# AT32F405xx_v2 register map
Vendor: Keil; Series: AT32F405; File version: 1.0
CPU: CM4 r0p1, little endian, no MPU, FPU, 4 interrupt priority bits
Registers are 32-bit, read-write, reset 0x0 unless marked. A register's access mark holds for its fields unless they carry their own. Offsets are from the block's base; [hi:lo] are bit positions; {n}, {i} and the like mark numbered series; 'fields as' and 'values as' point back to an identical list.

## USB_OTGHS_HOST — USB on the go high speed
Base 0x40040400
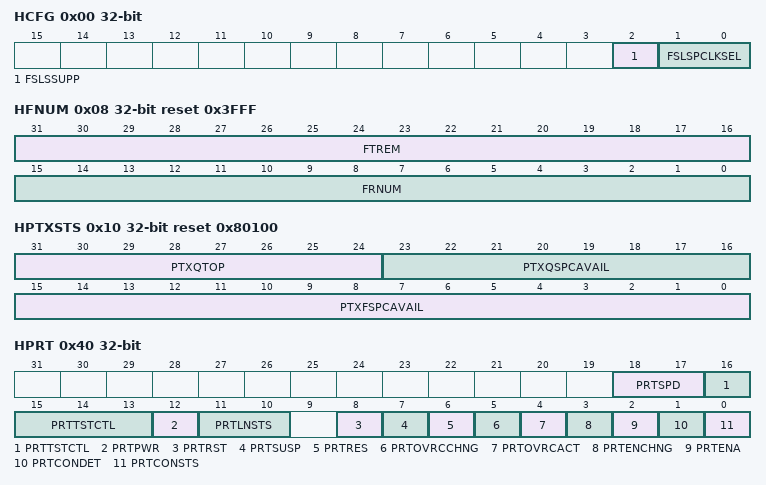
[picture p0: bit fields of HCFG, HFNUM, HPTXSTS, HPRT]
0x00 HCFG — OTGHS host configuration register (OTGHS_HCFG)
  [2] FSLSSUPP ro — FS- and LS-only support
  [1:0] FSLSPCLKSEL — FS/LS PHY clock select
0x04 HFIR reset 0xEA60 — OTGHS Host frame interval register
  [15:0] FRINT — Frame interval
0x08 HFNUM ro reset 0x3FFF — OTGHS host frame number/frame time remaining register (OTGHS_HFNUM)
  [31:16] FTREM — Frame time remaining
  [15:0] FRNUM — Frame number
0x10 HPTXSTS reset 0x80100 — OTGHS_Host periodic transmit FIFO/queue status register (OTGHS_HPTXSTS)
  [31:24] PTXQTOP ro — Top of the periodic transmit request queue
  [23:16] PTXQSPCAVAIL ro — Periodic transmit request queue space available
  [15:0] PTXFSPCAVAIL ro — Periodic transmit data FIFO space available
0x14 HAINT ro — OTGHS Host all channels interrupt register
  [15:0] HAINT — Channel interrupts
0x18 HAINTMSK — OTGHS host all channels interrupt mask register
  [15:0] HAINTMSK — Channel interrupt mask
0x40 HPRT — OTGHS host port control and status register (OTGHS_HPRT)
  [18:17] PRTSPD ro — Port speed
  [16:13] PRTTSTCTL — Port test control
  [12] PRTPWR — Port power
  [11:10] PRTLNSTS ro — Port line status
  [8] PRTRST — Port reset
  [7] PRTSUSP — Port suspend
  [6] PRTRES — Port resume
  [5] PRTOVRCCHNG — Port overcurrent change
  [4] PRTOVRCACT ro — Port overcurrent active
  [3] PRTENCHNG — Port enable/disable change
  [2] PRTENA — Port enable
  [1] PRTCONDET — Port connect detected
  [0] PRTCONSTS ro — Port connect status
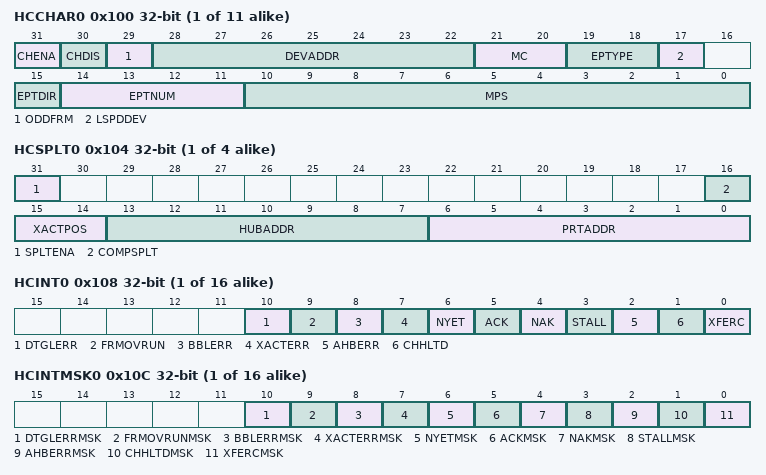
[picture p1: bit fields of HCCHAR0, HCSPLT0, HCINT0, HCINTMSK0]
{0x100+0x20*i} HCCHAR{i} (i=0..10) — OTGHS host channel-{i} characteristics register (OTGHS_HCCHAR{i})
  [31] CHENA — Channel enable
  [30] CHDIS — Channel disable
  [29] ODDFRM — Odd frame
  [28:22] DEVADDR — Device address
  [21:20] MC — Multicount
  [19:18] EPTYPE — Endpoint type
  [17] LSPDDEV — Low-speed device
  [15] EPTDIR — Endpoint direction
  [14:11] EPTNUM — Endpoint number
  [10:0] MPS — Maximum packet size
{0x104+0x20*i} HCSPLT{i} (i=0..3) — Host Channel {i} Split Control Register
  [31] SPLTENA — Split Enable
  [16] COMPSPLT — Do Complete Split
  [15:14] XACTPOS — Transaction Position
  [13:7] HUBADDR — Hub Address
  [6:0] PRTADDR — Port Address
{0x108+0x20*i} HCINT{i} (i=0..15) — OTGHS host channel-{i} interrupt register (OTGHS_HCINT{i})
  [10] DTGLERR — Data toggle error
  [9] FRMOVRUN — Frame overrun
  [8] BBLERR — Babble error
  [7] XACTERR — Transaction error
  [6] NYET — NYET Response Received interrupt
  [5] ACK — ACK response received/transmitted interrupt
  [4] NAK — NAK response received interrupt
  [3] STALL — STALL response received interrupt
  [2] AHBERR — AHB Error
  [1] CHHLTD — Channel halted
  [0] XFERC — Transfer completed
{0x10C+0x20*i} HCINTMSK{i} (i=0..15) — OTGHS host channel-{i} mask register (OTGHS_HCINTMSK{i})
  [10] DTGLERRMSK — Data toggle error mask
  [9] FRMOVRUNMSK — Frame overrun mask
  [8] BBLERRMSK — Babble error mask
  [7] XACTERRMSK — Transaction error mask
  [6] NYETMSK — NYET Response Received interrupt mask
  [5] ACKMSK — ACK response received/transmitted interrupt mask
  [4] NAKMSK — NAK response received interrupt mask
  [3] STALLMSK — STALL response received interrupt mask
  [2] AHBERRMSK — AHB Error Mask
  [1] CHHLTDMSK — Channel halted mask
  [0] XFERCMSK — Transfer completed mask
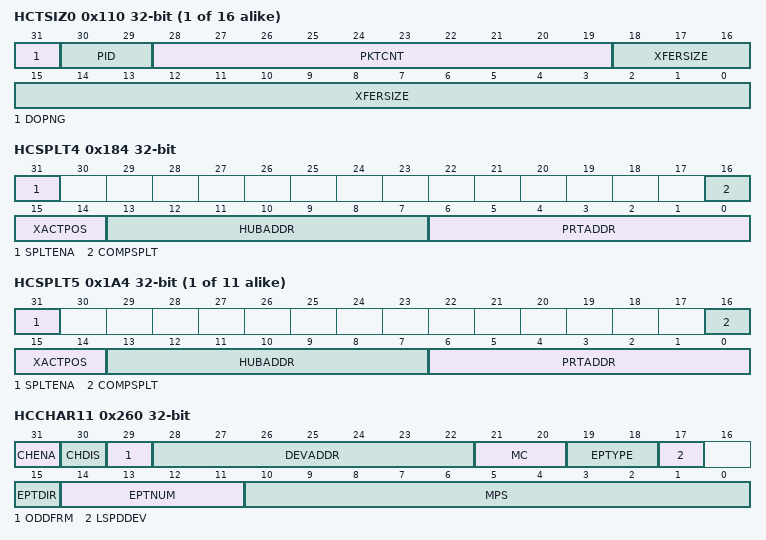
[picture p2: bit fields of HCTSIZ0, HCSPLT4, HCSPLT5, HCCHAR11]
{0x110+0x20*i} HCTSIZ{i} (i=0..15) — OTGHS host channel-{i} transfer size register
  [31] DOPNG — Do Ping
  [30:29] PID
  [28:19] PKTCNT — Packet count
  [18:0] XFERSIZE — Transfer size
{0x114+0x20*i} HCDMA{i} (i=0..15) — Host channel {i} DMA address register
  [31:0] DMAADDR — DMA Address
0x184 HCSPLT4 — Host Channel 1 Split Control Register
  fields as HCSPLT0
{0x104+0x20*i} HCSPLT{i} (i=5..15) — Host Channel {i} Split Control Register
  fields as HCSPLT0
0x260 HCCHAR11 — OTGHS host channel-7 characteristics register (OTGHS_HCCHAR11)
  fields as HCCHAR0
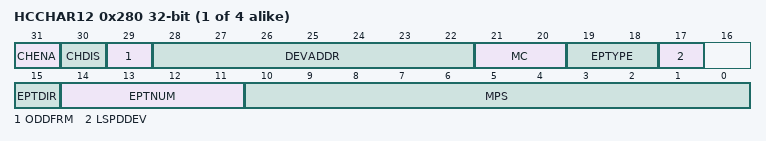
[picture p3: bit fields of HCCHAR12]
{0x100+0x20*i} HCCHAR{i} (i=12..15) — OTGHS host channel-{i} characteristics register (OTGHS_HCCHAR{i})
  fields as HCCHAR0

## Notices in the file
Copyright (C) 2012-2014 ARM Limited. All rights reserved.
Purpose: System Viewer Description (SVD) Example (Schema Version 1.1)
This is a description of a none-existent and incomplete device
for demonstration purposes only.
Redistribution and use in source and binary forms, with or without
modification, are permitted provided that the following conditions are met:
- Redistributions of source code must retain the above copyright
notice, this list of conditions and the following disclaimer.
- Redistributions in binary form must reproduce the above copyright
notice, this list of conditions and the following disclaimer in the
documentation and/or other materials provided with the distribution.
- Neither the name of ARM nor the names of its contributors may be used
to endorse or promote products derived from this software without
specific prior written permission.
THIS SOFTWARE IS PROVIDED BY THE COPYRIGHT HOLDERS AND CONTRIBUTORS "AS IS"
AND ANY EXPRESS OR IMPLIED WARRANTIES, INCLUDING, BUT NOT LIMITED TO, THE
IMPLIED WARRANTIES OF MERCHANTABILITY AND FITNESS FOR A PARTICULAR PURPOSE
ARE DISCLAIMED. IN NO EVENT SHALL COPYRIGHT HOLDERS AND CONTRIBUTORS BE
LIABLE FOR ANY DIRECT, INDIRECT, INCIDENTAL, SPECIAL, EXEMPLARY, OR
CONSEQUENTIAL DAMAGES (INCLUDING, BUT NOT LIMITED TO, PROCUREMENT OF
SUBSTITUTE GOODS OR SERVICES; LOSS OF USE, DATA, OR PROFITS; OR BUSINESS
INTERRUPTION) HOWEVER CAUSED AND ON ANY THEORY OF LIABILITY, WHETHER IN
CONTRACT, STRICT LIABILITY, OR TORT (INCLUDING NEGLIGENCE OR OTHERWISE)
ARISING IN ANY WAY OUT OF THE USE OF THIS SOFTWARE, EVEN IF ADVISED OF THE
POSSIBILITY OF SUCH DAMAGE.
